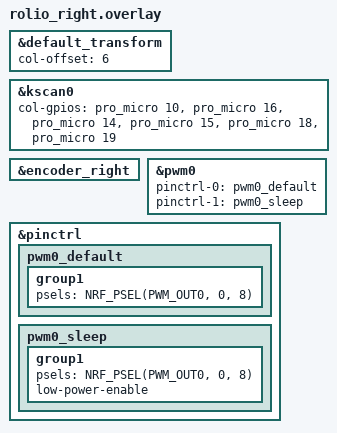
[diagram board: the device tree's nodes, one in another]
#include "rolio.dtsi"

&default_transform {
    col-offset = <6>;
};

&kscan0 {
    col-gpios
        = <&pro_micro 10 GPIO_ACTIVE_HIGH>
        , <&pro_micro 16 GPIO_ACTIVE_HIGH>
        , <&pro_micro 14 GPIO_ACTIVE_HIGH>
        , <&pro_micro 15 GPIO_ACTIVE_HIGH>
        , <&pro_micro 18 GPIO_ACTIVE_HIGH>
        , <&pro_micro 19 GPIO_ACTIVE_HIGH>
        ;
};

&encoder_right {
    status = "okay";
};

&pwm0 {
  status = "okay";
  pinctrl-0 = <&pwm0_default>;
  pinctrl-1 = <&pwm0_sleep>;
  pinctrl-names = "default", "sleep";
};

&pinctrl {
    pwm0_default: pwm0_default {
        group1 {
            // Use P0.08 for LED backlight
            psels = <NRF_PSEL(PWM_OUT0, 0, 8)>;
          };
    };

    pwm0_sleep: pwm0_sleep {
        group1 {
            // Use P0.08 for LED backlight
            psels = <NRF_PSEL(PWM_OUT0, 0, 8)>;
            low-power-enable;
          };
    };
};
